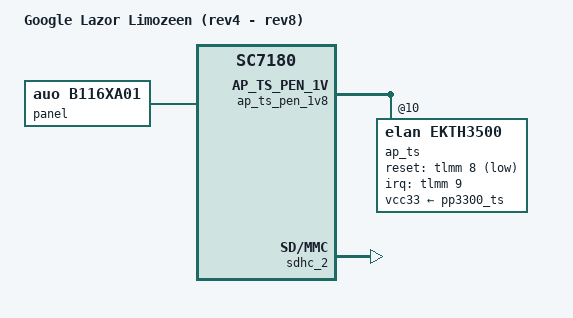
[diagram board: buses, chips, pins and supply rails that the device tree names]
// SPDX-License-Identifier: (GPL-2.0+ OR MIT)
/*
 * Google Lazor Limozeen board device tree source
 *
 * Copyright 2021 Google LLC.
 */

/dts-v1/;

#include "sc7180-trogdor.dtsi"
#include "sc7180-trogdor-ti-sn65dsi86.dtsi"
#include "sc7180-trogdor-lazor.dtsi"
#include "sc7180-trogdor-lte-sku.dtsi"
#include "sc7180-trogdor-rt5682i-sku.dtsi"


/ {
	model = "Google Lazor Limozeen (rev4 - rev8)";
	compatible = "google,lazor-rev4-sku4", "google,lazor-rev5-sku4",
		"google,lazor-rev6-sku4", "google,lazor-rev7-sku4",
		"google,lazor-rev8-sku4", "qcom,sc7180";
};

/delete-node/&ap_ts;

&ap_ts_pen_1v8 {
	ap_ts: touchscreen@10 {
		compatible = "elan,ekth3500";
		reg = <0x10>;
		pinctrl-names = "default";
		pinctrl-0 = <&ts_int_l>, <&ts_reset_l>;

		interrupt-parent = <&tlmm>;
		interrupts = <9 IRQ_TYPE_LEVEL_LOW>;

		vcc33-supply = <&pp3300_ts>;

		reset-gpios = <&tlmm 8 GPIO_ACTIVE_LOW>;
	};
};

&panel {
	compatible = "auo,b116xa01";
};

&sdhc_2 {
	status = "okay";
};
